# G32F031 register map
File version: 1.0
CPU: CM0PLUS r0p1, little endian, no MPU, no FPU, 2 interrupt priority bits
Registers are 32-bit, read-write, reset 0x0 unless marked. A register's access mark holds for its fields unless they carry their own. Offsets are from the block's base; lines under a group give offsets from that group; [hi:lo] are bit positions; {n}, {i} and the like mark numbered series; 'fields as' and 'values as' point back to an identical list; <NAME> marks a mode.

## Memory map
0x40000000 PMU size 0x400 — Power Manage Unit
0x40000400 SCU size 0x400 — System Control Unit
0x40000800 EINT size 0x400 — External interrupt/event controller
0x40000C00 ATMR size 0x400 — Advance timer
0x40001000 GTMR size 0x400 — General purpose timer
0x40001800 BTMR0 size 0x400 — Base timer
0x40001C00 BTMR1 size 0x400 — Base timer
0x40002000 LPTMR size 0x400 — Low-power timer
0x40002800 IWDT size 0x400 — Independent watchdog
0x40002C00 WWDT size 0x400 — Window watchdog
0x40003000 SPI size 0x400 — Serial peripheral interface
0x40003800 USART size 0x400 — Universal asynchronous receiver transmitter
0x40003C00 UART size 0x400 — Universal asynchronous receiver transmitter
0x40004400 I2C size 0x400 — Inter-Integrated Circuit
0x40005400 ADC size 0x400 — Analog-to-digital converter
0x40005800 OPA size 0x400
0x40005C00 COMP0 size 0x400 — Comparator
0x40006000 COMP1 size 0x400 — Comparator
0x40020000 DMA size 0x400 — DMA controller
0x40020400 RCC size 0x400 — Reset and clock control
0x40020800 FLASH size 0x400 — Flash memory controller
0x40020C00 CRC size 0x400 — Cryptographic processor
0x40021000 DIV size 0x400
0x48000000 GPIOA size 0x400 — General-purpose I/Os
0x48000400 GPIOB size 0x400 — General-purpose I/Os

## Interrupts
0 WWDT — Window Watchdog global interrupt
1 PVD (PMU, RCC) — PVD global interrupt
3 FLASH — FLASH global interrupt
4 RCC — RCC global interrupt
5 EINT0_1 (EINT) — EINT Line 0 to 1 global interrupt
6 EINT2_3 (EINT) — EINT Line 2 to 3 global interrupt
7 EINT4_15 (EINT) — EINT Line 4 to 15 global interrupts
9 DMA_CH0 (DMA) — DMA_CH0 global interrupt
10 DMA_CH1 (DMA) — DMA_CH1 global interrupts
12 ADC — ADC global interrupt
13 ATMR_BRK_UP_TRG_COM (ATMR) — ATMR_BRK_UP_TRG_COM global interrupt
14 ATMR_CC (ATMR) — ATMR_CC global interrupt
15 GTMR — GTMR interrupt
17 BTMR0 — BTMR0 global interrupt
18 BTMR1 — BTMR1 global interrupt
19 LPTMR — LPTMR global interrupt
21 COMP0 — COMP0 global interrupt
22 COMP1_2_3 (COMP1) — COMP1/2/3 global interrupt
23 I2C1 (I2C) — I2C1 global interrupt
25 SPI1 (SPI) — SPI1 global interrupt
27 USART0 (USART) — USART0 global interrupt
28 UART0 (UART) — UART0 global interrupt

## PMU — Power Manage Unit
Base 0x40000000
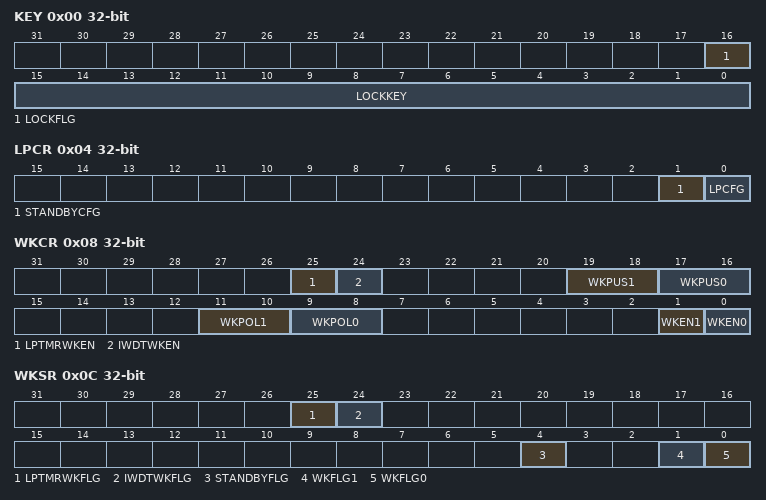
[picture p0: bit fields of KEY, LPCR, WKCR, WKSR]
0x00 KEY access per field — Read-Write Protection Register
  [16] LOCKFLG ro — PMU register lock flag
  [15:0] LOCKKEY wo — Counter enable
0x04 LPCR — Low Power Mode Register
  [1] STANDBYCFG — STANDBY Operation Mode
  [0] LPCFG — Low Power Mode
0x08 WKCR — Low-power wake-up control register
  [25] LPTMRWKEN — Enable LPTMR wake-up in STANDBY mode
  [24] IWDTWKEN — Enable IWDT wake-up in STANDBY mode
  [19:18] WKPUS1 — Wake-up pin 1 pull-up/pull-down control in STANDBY mode
  [17:16] WKPUS0 — Wake-up pin 0 pull-up/pull-down control in STANDBY mode
  [11:10] WKPOL1 — Wake-up polarity of pin 1 for STANDBY
  [9:8] WKPOL0 — Wake-up polarity of pin 0 for STANDBY
  [1] WKEN1 — Enable wake-up from STANDBY by pin 1
  [0] WKEN0 — Enable wake-up from STANDBY by pin 0
0x0C WKSR — Low Power Wake-up Status Register
  [25] LPTMRWKFLG — LPTMR to STANDBY wake-up flag
  [24] IWDTWKFLG — IWDT Standby Wake-up Flag
  [4] STANDBYFLG — STANDBY Event Flag
  [1] WKFLG1 — Wake-up pin 1 to STANDBY wake-up flag
  [0] WKFLG0 — Wake-up pin 0 to STANDBY wake-up flag
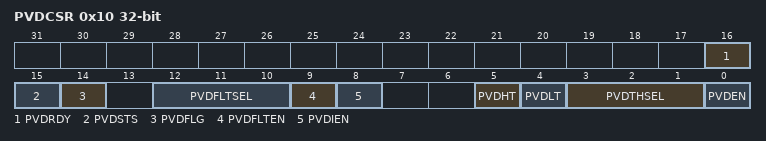
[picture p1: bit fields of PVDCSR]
0x10 PVDCSR — PVD Control/Status Register
  [16] PVDRDY — PVD Ready
  [15] PVDSTS — PVD Monitoring Results Output
  [14] PVDFLG — PVD Monitoring Event Flag
  [12:10] PVDFLTSEL — PVD filter length select
  [9] PVDFLTEN — PVD filter enable
  [8] PVDIEN — PVD monitoring event interrupt enable
  [5] PVDHT — PVD above threshold voltage event monitoring.
  [4] PVDLT — PVD below threshold voltage event detection.
  [3:1] PVDTHSEL — PVD threshold voltage configuration
  [0] PVDEN — PVD Enable
